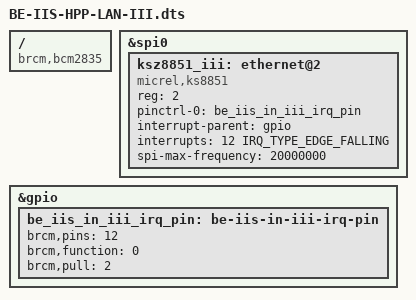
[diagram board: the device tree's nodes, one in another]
/dts-v1/;
/plugin/;

#include <dt-bindings/interrupt-controller/irq.h>
#include <dt-bindings/gpio/gpio.h>

/ {
	compatible = "brcm,bcm2835", "brcm,bcm2711", "brcm,bcm2712";

	fragment@0 {
		target = <&spi0>;
		__overlay__ {
			#address-cells = <1>;
			#size-cells = <0>;

			ksz8851_iii: ethernet@2 {
				compatible = "micrel,ks8851";
				reg = <2>;

                                pinctrl-names = "default";
                                pinctrl-0 = <&be_iis_in_iii_irq_pin>;
                                
				interrupt-parent = <&gpio>;
				interrupts = <12 IRQ_TYPE_EDGE_FALLING>;

				spi-max-frequency = <20000000>;
				status = "okay";
			};
		};
	};

/* GPIO12 as input, pull-up (IRQ pin) */
fragment@2 {
    target = <&gpio>;
    __overlay__ {
        be_iis_in_iii_irq_pin: be-iis-in-iii-irq-pin {
            brcm,pins = <12>;
            brcm,function = <0>;
            brcm,pull = <2>;
        };
    };
};

	__overrides__ {
		speed   = <&ksz8851_iii>, "spi-max-frequency:0";
	};
};
